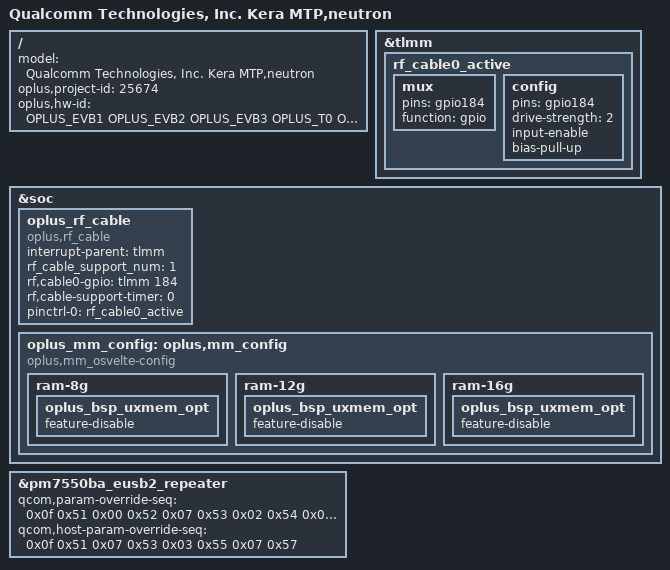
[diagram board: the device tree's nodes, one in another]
/dts-v1/;
/plugin/;
#include <dt-bindings/oplus/hw-id.h>
#include "../qcom/kera-mtp-qca6750-ufs3-overlay.dts"
#include "kera_overlay_common.dtsi"
#include "neutron_overlay_common.dtsi"
#include "oplus_uff/oplus-uff-24625.dtsi"
#include "oplus_nfc/neutron_nfc_pn560_mixed.dtsi"
#include "oplus_misc/oplus-misc-24625.dtsi"
#include "oplus_chg/neutron/oplus-chg-neutron-common-25674.dtsi"
#include "tp/neutron-oplus-tp-24625.dtsi"
#include "sensor/neutron-sensor-24625.dtsi"
#include "oplus_misc/oplus-misc-breathlight-24625.dtsi"

/ {
    model = "Qualcomm Technologies, Inc. Kera MTP,neutron";

    oplus,project-id = <25674>;
    oplus,hw-id = <OPLUS_EVB1 OPLUS_EVB2 OPLUS_EVB3 OPLUS_T0 OPLUS_EVT1 OPLUS_EVT2 OPLUS_DVT1 OPLUS_DVT2 OPLUS_PVT1>;
};
&tlmm {
  //#ifdef OPLUS_FEATURE_RF_CABLE_DETECT
  rf_cable0_active: rf_cable0_active {
      mux {
          pins = "gpio184";
          function = "gpio";
      };
      config {
          pins = "gpio184";
          drive-strength = <2>;
          input-enable;
          bias-pull-up;
      };
  };
  //#endif /* OPLUS_FEATURE_RF_CABLE_DETECT */
};
&soc {
  //#ifdef OPLUS_FEATURE_RF_CABLE_DETECT
  oplus_rf_cable {
      compatible = "oplus,rf_cable";
      interrupt-parent = <&tlmm>;
      rf_cable_support_num = <1>;
      rf,cable0-gpio = <&tlmm 184 0>;
      rf,cable-support-timer = <0>;
      pinctrl-names = "rf_cable_active";
      pinctrl-0 = <&rf_cable0_active>;
  };
  //#endif /* OPLUS_FEATURE_RF_CABLE_DETECT */
};
&soc {
	oplus_mm_config: oplus,mm_config {
		compatible = "oplus,mm_osvelte-config";
		ram-8g {
			oplus_bsp_uxmem_opt {
				feature-disable;
			};
		};
		ram-12g {
			oplus_bsp_uxmem_opt {
				feature-disable;
			};
		};
		ram-16g {
			oplus_bsp_uxmem_opt {
				feature-disable;
			};
		};
	};
};

&pm7550ba_eusb2_repeater {
	qcom,param-override-seq = <0x0f 0x51 0x00 0x52 0x07 0x53 0x02 0x54 0x03 0x55 0x03 0x56 0x07 0x57>;
	qcom,host-param-override-seq = <0x0f 0x51 0x07 0x53 0x03 0x55 0x07 0x57>;
};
